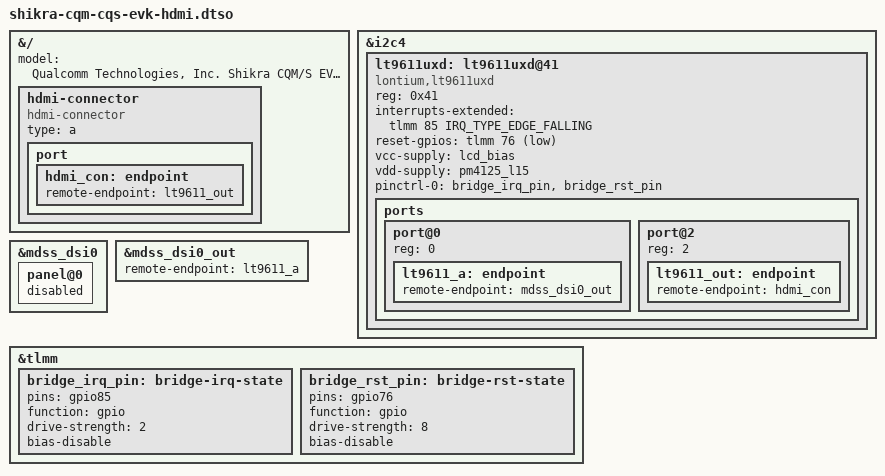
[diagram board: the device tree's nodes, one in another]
// SPDX-License-Identifier: BSD-3-Clause
/*
 * Copyright (c) Qualcomm Technologies, Inc. and/or its subsidiaries.
 */

/dts-v1/;
/plugin/;

#include <dt-bindings/gpio/gpio.h>
#include <dt-bindings/interrupt-controller/irq.h>

&{/} {
	model = "Qualcomm Technologies, Inc. Shikra CQM/S EVK HDMI";

	hdmi-connector {
		compatible = "hdmi-connector";
		type = "a";

		port {
			hdmi_con: endpoint {
				remote-endpoint = <&lt9611_out>;
			};
		};
	};
};

&i2c4 {
	#address-cells = <1>;
	#size-cells = <0>;

	status = "okay";

	lt9611uxd: lt9611uxd@41 {
		compatible = "lontium,lt9611uxd";
		reg = <0x41>;
		interrupts-extended = <&tlmm 85 IRQ_TYPE_EDGE_FALLING>;
		reset-gpios = <&tlmm 76 GPIO_ACTIVE_LOW>;
		vcc-supply = <&lcd_bias>;
		vdd-supply = <&pm4125_l15>;

		pinctrl-0 = <&bridge_irq_pin &bridge_rst_pin>;
		pinctrl-names = "default";

		ports {
			#address-cells = <1>;
			#size-cells = <0>;

			port@0 {
				reg = <0>;

				lt9611_a: endpoint {
					remote-endpoint = <&mdss_dsi0_out>;
				};
			};

			port@2 {
				reg = <2>;

				lt9611_out: endpoint {
					remote-endpoint = <&hdmi_con>;
				};
			};
		};
	};
};

&mdss_dsi0 {
	panel@0 {
		status = "disabled";
	};
};

&mdss_dsi0_out {
	remote-endpoint = <&lt9611_a>;
};

&tlmm {
	bridge_irq_pin: bridge-irq-state {
		pins = "gpio85";
		function = "gpio";
		drive-strength = <2>;
		bias-disable;
	};

	bridge_rst_pin: bridge-rst-state {
		pins = "gpio76";
		function = "gpio";
		drive-strength = <8>;
		bias-disable;
	};
};
